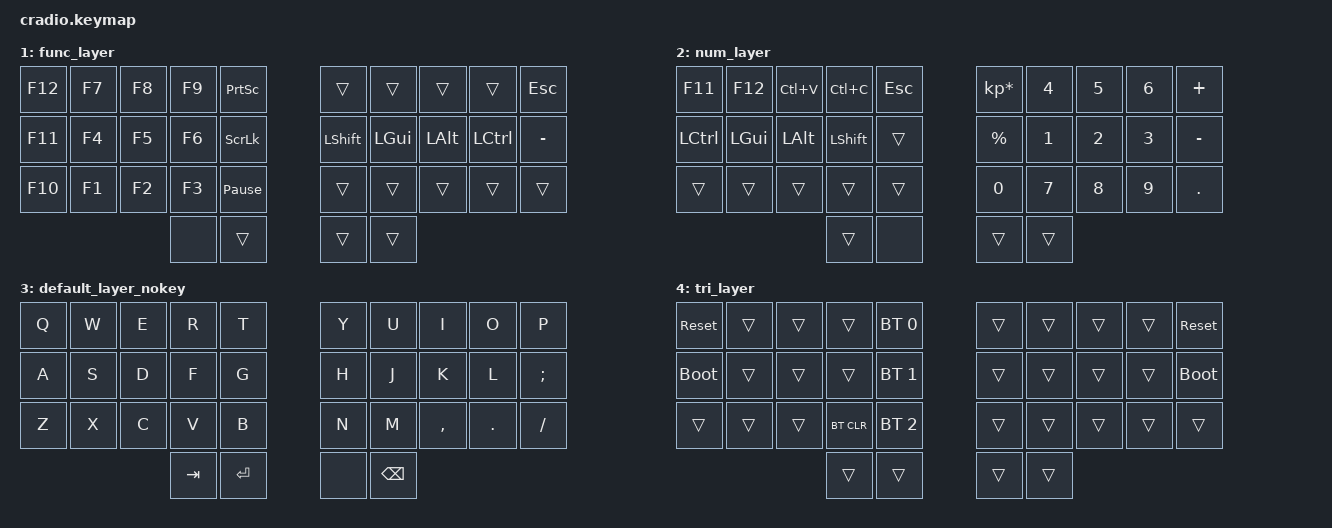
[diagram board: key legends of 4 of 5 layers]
// Copyright (c) 2022 The ZMK Contributors
// SPDX-License-Identifier: MIT

#include <behaviors.dtsi>
#include <dt-bindings/zmk/keys.h>
#include <dt-bindings/zmk/bt.h>


// Home row mods macro
#define HRML(k1,k2,k3,k4) &ht LCTRL k1  &ht LGUI k2  &ht LALT k3  &ht LSHFT k4
#define HRMR(k1,k2,k3,k4) &ht LSHFT k1  &ht LALT k2  &ht LGUI k3  &ht LCTRL k4

/ {
    combos {
        compatible = "zmk,combos";

        bracket {
            bindings = <&kp LEFT_PARENTHESIS>;
            key-positions = <5 6>;
            layers = <0 1>;
        };

        bracket_r {
            bindings = <&kp RIGHT_PARENTHESIS>;
            key-positions = <7 6>;
            layers = <0 1>;
        };

        lb {
            bindings = <&kp LEFT_BRACKET>;
            key-positions = <7 8>;
            layers = <0 1>;
        };

        rb {
            bindings = <&kp RIGHT_BRACKET>;
            key-positions = <9 8>;
            layers = <0 1>;
        };

        lf {
            bindings = <&kp LEFT_BRACE>;
            key-positions = <6 8>;
            layers = <0 1>;
        };

        rba {
            bindings = <&kp RIGHT_BRACE>;
            key-positions = <6 9>;
            layers = <0 1>;
        };


        caret {
            bindings = <&kp CARET>;
            key-positions = <1 0>;
            layers = <0 1>;
        };

        underscore {
            bindings = <&kp UNDERSCORE>;
            key-positions = <13 14>;
            layers = <0 1>;
        };

        pipe {
            bindings = <&kp PIPE>;
            key-positions = <22 23>;
            layers = <0 1>;
        };

        and {
            bindings = <&kp AMPERSAND>;
            key-positions = <1 3>;
            layers = <0 1>;
        };

        at {
            bindings = <&kp AT>;
            key-positions = <1 12>;
            layers = <0 1>;
        };

        tick {
            bindings = <&kp GRAVE>;
            key-positions = <29 30>;
            layers = <0 1>;
        };

        hash {
            bindings = <&kp HASH>;
            key-positions = <2 13>;
            layers = <0 1>;
        };

        dollar {
            bindings = <&kp DLLR>;
            key-positions = <3 4>;
            layers = <0 1>;
        };

        equal {
            bindings = <&kp EQUAL>;
            key-positions = <25 26>;
            layers = <0 1>;
        };

        tilde {
            bindings = <&kp TILDE>;
            key-positions = <26 28>;
            layers = <0 1>;
        };

        exam {
            bindings = <&kp EXCL>;
            key-positions = <20 21>;
            layers = <0 1>;
        };

        bslh {
            bindings = <&kp BSLH>;
            key-positions = <21 23>;
            layers = <0 1>;
        };

        sqt {
            bindings = <&kp SQT>;
            key-positions = <22 23>;
            layers = <0 1>;
        };

        dqt {
            bindings = <&kp DQT>;
            key-positions = <23 24>;
            layers = <0 1>;
        };

        left {
            bindings = <&kp LEFT>;
            key-positions = <26 17>;
            layers = <0 1>;
        };

        right {
            bindings = <&kp RIGHT>;
            key-positions = <28 17>;
            layers = <0 1>;
        };

        up {
            bindings = <&kp UP>;
            key-positions = <7 16>;
            layers = <0 1>;
        };

        down {
            bindings = <&kp DOWN>;
            key-positions = <27 16>;
            layers = <0 1>;
        };
    };
    behaviors {

        ht: hold_tap {
            label = "hold_tap";
            compatible = "zmk,behavior-hold-tap";
            #binding-cells = <2>;
            flavor = "tap-preferred";
            tapping-term-ms = <220>;
            quick-tap-ms = <150>;
            global-quick-tap;
            bindings = <&kp>, <&kp>;
        };
    };

    conditional_layers {
        compatible = "zmk,conditional-layers";
        tri_layer {
            if-layers = <1 2 3>;
            then-layer = <4>;
        };
    };

    keymap {
        compatible = "zmk,keymap";
        default_layer {
            bindings = <
        //╭──────────┬──────────┬──────────┬──────────┬──────────╮   ╭──────────┬──────────┬──────────┬──────────┬──────────╮
        //│  Q       │  W       │  E       │  R       │  T       │   │  Y       │  U       │  I       │  O       │  P       │
            &kp Q      &kp W       &kp E    &kp R        &kp T       &kp  Y    &kp U      &kp I        &kp O    &kp P
        //├──────────┼──────────┼──────────┼──────────┼──────────┤   ├──────────┼──────────┼──────────┼──────────┼──────────┤
        //│  A       │  S       │  D       │  F       │  G       │   │  H       │  J       │  K       │  L       │ ;:       │
            HRML(A,        S,         D,         F)     &kp G         HRMR( H,      J,       K,           L)     &kp SEMI
        //├──────────┼──────────┼──────────┼──────────┼──────────┤   ├──────────┼──────────┼──────────┼──────────┼──────────┤
        //│  Z       │  X       │  C       │  V       │  B       │   │  N       │  M       │ , <      │ . >      │ / ?      │
            &kp Z      &kp X      &kp C      &kp V      &kp B          &kp N      &kp M      &kp COMMA   &kp DOT    &kp FSLH
        //╰──────────┴──────────┴──────────┼──────────┼──────────┤   ├──────────┼──────────┼──────────┴──────────┴──────────╯
                                            &lt 1 TAB  &lt 2 ENTER        &lt 3 SPACE &kp BSPC
        //                                 ╰──────────┴──────────╯   ╰──────────┴──────────╯
            >;
        };

        func_layer {
            bindings =<
        //╭──────────┬──────────┬──────────┬──────────┬──────────╮   ╭──────────┬──────────┬──────────┬──────────┬──────────╮
        //│          │          │          │          │          │   │          │  4       │  5       │  6       │    +     │
            &kp F12    &kp F7     &kp F8     &kp F9  &kp PRINTSCREEN     &trans   &trans    &trans      &trans     &kp ESC
        //├──────────┼──────────┼──────────┼──────────┼──────────┤   ├──────────┼──────────┼──────────┼──────────┼──────────┤
        //│          │          │          │     \    │    -     │   │    %     │  1       │  2       │ 3        │   -      │
            &kp F11    &kp F4      &kp F5      &kp F6  &kp SCROLLLOCK   &kp LSHFT  &kp LGUI   &kp LALT  &kp LCTRL   &kp MINUS
        //├──────────┼──────────┼──────────┼──────────┼──────────┤   ├──────────┼──────────┼──────────┼──────────┼──────────┤
        //│    F1    │   F2     │          │          │    "     │   │    0     │  7       │   8      │     9    │    .     │
            &kp F10    &kp F1      &kp F2    &kp F3  &kp PAUSE_BREAK     &trans   &trans    &trans      &trans     &trans
        //╰──────────┴──────────┴──────────┼──────────┼──────────┤   ├──────────┼──────────┼──────────┴──────────┴──────────╯
                                            &none       &trans         &trans    &trans
        //                                 ╰──────────┴──────────╯   ╰──────────┴──────────╯
            >;
        };


        num_layer {
            bindings =<
        //╭──────────┬──────────┬──────────┬──────────┬──────────╮   ╭──────────┬──────────┬──────────┬──────────┬──────────╮
        //│          │          │          │          │          │   │   *      │  4       │  5       │  6       │    +     │
            &kp F11   &kp F12    &kp LC(V)  &kp LC(C)  &kp ESC        &kp KP_MULTIPLY &kp N4  &kp N5     &kp N6    &kp PLUS
        //├──────────┼──────────┼──────────┼──────────┼──────────┤   ├──────────┼──────────┼──────────┼──────────┼──────────┤
        //│          │          │          │          │          │   │   %      │  1       │  2       │ 3        │   -      │
           &kp LCTRL  &kp LEFT_GUI &kp LEFT_ALT &kp LEFT_SHIFT &trans         &kp PRCNT    &kp N1     &kp N2      &kp N3  &kp MINUS
        //├──────────┼──────────┼──────────┼──────────┼──────────┤   ├──────────┼──────────┼──────────┼──────────┼──────────┤
        //│    F1    │   F2     │          │          │          │   │    0     │  7       │   8      │     9    │     .    │
            &trans    &trans     &trans      &trans     &trans         &kp N0    &kp N7     &kp N8      &kp N9      &kp DOT
        //╰──────────┴──────────┴──────────┼──────────┼──────────┤   ├──────────┼──────────┼──────────┴──────────┴──────────╯
                                            &trans     &none          &trans    &trans
        //                                 ╰──────────┴──────────╯   ╰──────────┴──────────╯
            >;
        };

        default_layer_nokey {
            bindings = <
        //╭──────────┬──────────┬──────────┬──────────┬──────────╮   ╭──────────┬──────────┬──────────┬──────────┬──────────╮
        //│  Q       │  W       │  E       │  R       │  T       │   │  Y       │  U       │  I       │  O       │  P       │
            &kp Q      &kp W      &kp E    &kp R        &kp T       &kp  Y    &kp U      &kp I        &kp O    &kp P
        //├──────────┼──────────┼──────────┼──────────┼──────────┤   ├──────────┼──────────┼──────────┼──────────┼──────────┤
        //│  A       │  S       │  D       │  F       │  G       │   │  H       │  J       │  K       │  L       │ ;:       │
            &kp A       &kp S      &kp D      &kp F     &kp G           &kp H      &kp J       &kp K     &kp L     &kp SEMI
        //├──────────┼──────────┼──────────┼──────────┼──────────┤   ├──────────┼──────────┼──────────┼──────────┼──────────┤
        //│  Z       │  X       │  C       │  V       │  B       │   │  N       │  M       │ , <      │ . >      │ / ?      │
            &kp Z      &kp X      &kp C      &kp V      &kp B          &kp N      &kp M      &kp COMMA   &kp DOT    &kp FSLH
        //╰──────────┴──────────┴──────────┼──────────┼──────────┤   ├──────────┼──────────┼──────────┴──────────┴──────────╯
                                            &kp TAB  &kp ENTER        &none    &kp BSPC
        //                                 ╰──────────┴──────────╯   ╰──────────┴──────────╯
            >;
        };
        tri_layer {
            bindings = <
        //╭──────────┬──────────┬──────────┬──────────┬──────────╮   ╭──────────┬──────────┬──────────┬──────────┬──────────╮
        //│ RESET    │          │          │          │PROFILE 0 │   │          │          │          │          │  RESEt  │
           &sys_reset  &trans     &trans     &trans    &bt BT_SEL 0    &trans     &trans     &trans     &trans    &sys_reset
        //├──────────┼──────────┼──────────┼──────────┼──────────┤   ├──────────┼──────────┼──────────┼──────────┼──────────┤
        //│BOOTLOADER│          │          │          │PROFILE 1 │   │          │          │          │          │BOOTLOADER│
          &bootloader  &trans     &trans     &trans    &bt BT_SEL 1    &trans     &trans     &trans     &trans    &bootloader
        //├──────────┼──────────┼──────────┼──────────┼──────────┤   ├──────────┼──────────┼──────────┼──────────┼──────────┤
        //│          │          │          │ CLEAR BT │PROFILE 2 │   │          │          │          │          │          │
            &trans     &trans     &trans    &bt BT_CLR &bt BT_SEL 2    &trans     &trans     &trans     &trans     &trans
        //╰──────────┴──────────┴──────────┼──────────┼──────────┤   ├──────────┼──────────┼──────────┴──────────┴──────────╯
                                             &trans     &trans         &trans     &trans
        //                                 ╰──────────┴──────────╯   ╰──────────┴──────────╯
            >;
        };
    };
};
